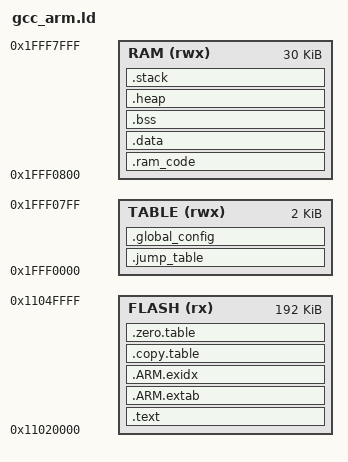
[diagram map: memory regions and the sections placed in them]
/* I copy this file from CMSIS_5/CMSIS/CoreValidation/Layer/Target/CM0/RTE/Device/ARMCM0 */
/******************************************************************************
 * @file     gcc_arm.ld
 * @brief    GNU Linker Script for Cortex-M based device
 * @version  V2.1.0
 * @date     04. August 2020
 ******************************************************************************/
/*
 * Copyright (c) 2009-2020 Arm Limited. All rights reserved.
 *
 * SPDX-License-Identifier: Apache-2.0
 *
 * Licensed under the Apache License, Version 2.0 (the License); you may
 * not use this file except in compliance with the License.
 * You may obtain a copy of the License at
 *
 * www.apache.org/licenses/LICENSE-2.0
 *
 * Unless required by applicable law or agreed to in writing, software
 * distributed under the License is distributed on an AS IS BASIS, WITHOUT
 * WARRANTIES OR CONDITIONS OF ANY KIND, either express or implied.
 * See the License for the specific language governing permissions and
 * limitations under the License.
 */

/*
 *-------- <<< Use Configuration Wizard in Context Menu >>> -------------------
 */

__ROM_BASE = 0x11020000;
__ROM_SIZE = 0x00030000; 

__ACTUAL_RAM_BASE = 0x1FFF0000;
__ACTUAL_RAM_SIZE = 0x00008000;

__TABLE_BASE = __ACTUAL_RAM_BASE;
__TABLE_SIZE = 0x00000800;

__RAM_BASE = __ACTUAL_RAM_BASE + __TABLE_SIZE;
__RAM_SIZE = __ACTUAL_RAM_SIZE - __TABLE_SIZE ; /* 32K */

/* in Bytes */
__STACK_SIZE = 0x00000600; /* 1.5K */
__HEAP_SIZE  = 0x00000D00; /* 3K */

/*
 *-------------------- <<< end of configuration section >>> -------------------
 */

MEMORY
{
  FLASH (rx)  : ORIGIN = __ROM_BASE, LENGTH = __ROM_SIZE
  RAM   (rwx) : ORIGIN = __RAM_BASE, LENGTH = __RAM_SIZE
  TABLE (rwx) : ORIGIN = __TABLE_BASE, LENGTH = __TABLE_SIZE
}

/* Linker script to place sections and symbol values. Should be used together
 * with other linker script that defines memory regions FLASH and RAM.
 * It references following symbols, which must be defined in code:
 *   Reset_Handler : Entry of reset handler
 *
 * It defines following symbols, which code can use without definition:
 *   __exidx_start
 *   __exidx_end
 *   __copy_table_start__
 *   __copy_table_end__
 *   __zero_table_start__
 *   __zero_table_end__
 *   __etext
 *   __data_start__
 *   __data_end__
 *   __bss_start__
 *   __bss_end__
 *   __end__
 *   end
 *   __HeapLimit
 *   __StackLimit
 *   __StackTop
 *   __initial_sp
 *   __stack
 */
ENTRY(Reset_Handler)

SECTIONS
{
  .  = ALIGN(4);

  .ram_code :
  {
    *(.text)
    *(.text.gatt*)
    *(.text.osal*)
    *(_section_sram_code_)
  } > RAM

  /*
  .rom_xip :
  */
  .text :
  {
    KEEP(*(.vectors))

    /* compile object file ended with `.obj` instead of `.o` in CMake */
    *gatt*.o*(.text*)
    *gattservapp*.o*(.text*)
    *l2cap*.o*(.text*)
    *att*.o*(.text*)
    *sm*.o*(.text*)
    *gap*.o*(.text*)
    *linkdb.o*(.text*)
    *simpleblecentral.o*(.text*)
    *simpleBLECentral*.o*(.text*)
    *central.o*(.text*)
    *(_section_xip_code_)
    *(_func_xip_code_.*)
    *(i.*)
    *(.text*)

    KEEP(*(.init))
    KEEP(*(.fini))

    /* .ctors */
    *crtbegin.o(.ctors)
    *crtbegin?.o(.ctors)
    *(EXCLUDE_FILE(*crtend?.o *crtend.o) .ctors)
    *(SORT(.ctors.*))
    *(.ctors)

    /* .dtors */
    *crtbegin.o(.dtors)
    *crtbegin?.o(.dtors)
    *(EXCLUDE_FILE(*crtend?.o *crtend.o) .dtors)
    *(SORT(.dtors.*))
    *(.dtors)

    *(.rodata*)

    KEEP(*(.eh_frame*))
  } > FLASH

  /*
  .text :
  {
    *(.text*)
  } > RAM
  */



  /* Generated by copilot */
  /* `--keep=jump_table_base  --keep=global_config` for Arm Compiler? */
  .jump_table :
  {
    KEEP(*(jump_table_mem_area))
  } > TABLE

  .global_config :
  {
    KEEP(*(global_config_area))
  } > TABLE

  .ARM.extab :
  {
    *(.ARM.extab* .gnu.linkonce.armextab.*)
  } > FLASH

  __exidx_start = .;
  .ARM.exidx :
  {
    *(.ARM.exidx* .gnu.linkonce.armexidx.*)
  } > FLASH
  __exidx_end = .;

  .copy.table :
  {
    . = ALIGN(4);
    __copy_table_start__ = .;

    LONG (__etext)
    LONG (__data_start__)
    LONG ((__data_end__ - __data_start__) / 4)

    __copy_table_end__ = .;
  } > FLASH

  .zero.table :
  {
    . = ALIGN(4);
    __zero_table_start__ = .;
    __zero_table_end__ = .;
  } > FLASH

  /**
   * Location counter can end up 2byte aligned with narrow Thumb code but
   * __etext is assumed by startup code to be the LMA of a section in RAM
   * which must be 4byte aligned 
   */
  __etext = ALIGN (4);

  .data : AT (__etext)
  {
    __data_start__ = .;
    *(vtable)
    *(.data)
    *(.data.*)

    /* All data end */
    __data_end__ = .;

  } > RAM

  .bss :
  {
    . = ALIGN(4);
    __bss_start__ = .;
    *(.bss)
    *(.bss.*)
    *(COMMON)
    . = ALIGN(4);
    __bss_end__ = .;
  } > RAM AT > RAM

  .heap (COPY) :
  {
    . = ALIGN(8);
    __end__ = .;
    PROVIDE(end = .);
    . = . + __HEAP_SIZE;
    . = ALIGN(8);
    __HeapLimit = .;
  } > RAM

  .stack (ORIGIN(RAM) + LENGTH(RAM) - __STACK_SIZE) (COPY) :
  {
    . = ALIGN(8);
    __StackLimit = .;
    . = . + __STACK_SIZE;
    . = ALIGN(8);
    __StackTop = .;
  } > RAM
  PROVIDE(__stack = __StackTop);
  /* I add this but not sure if it's usable */
  /* This symbol is only defined in `startup_ARMCM0.s` but not in the linker script */
  PROVIDE(__initial_sp = __StackTop);

  /* Check if data + heap + stack exceeds RAM limit */
  ASSERT(__StackLimit >= __HeapLimit, "region RAM overflowed with stack")
}
